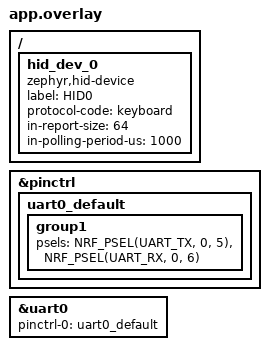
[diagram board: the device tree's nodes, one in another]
/ {
    hid_dev_0: hid_dev_0 {
        compatible = "zephyr,hid-device";
        label = "HID0";
        protocol-code = "keyboard";
        in-report-size = <64>;
        in-polling-period-us = <1000>;
    };
};

&pinctrl {
    uart0_default: uart0_default {
        group1 {
            psels = <NRF_PSEL(UART_TX, 0, 5)>,
                    <NRF_PSEL(UART_RX, 0, 6)>;
        };
    };
};

&uart0 {
    status = "okay";
    pinctrl-0 = <&uart0_default>;
    pinctrl-names = "default";
    /delete-property/ pinctrl-1;
};
